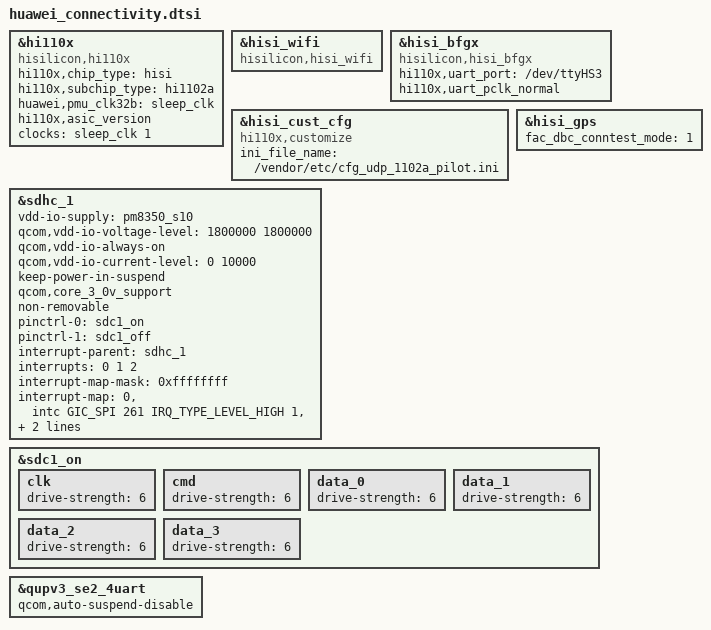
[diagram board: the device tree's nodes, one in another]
&hi110x {
	compatible = "hisilicon,hi110x","hisilicon,hi1102";
	status = "ok";
	hi110x,chip_type = "hisi";
	hi110x,subchip_type = "hi1102a";
	huawei,pmu_clk32b = "sleep_clk";
	hi110x,asic_version;
	clocks = <&sleep_clk 1>;
	clock-names = "sleep_clk";
};

&hisi_wifi {
	compatible = "hisilicon,hisi_wifi";
	status = "ok";
};

&hisi_bfgx {
	compatible = "hisilicon,hisi_bfgx";
	status = "ok";
	hi110x,uart_port = "/dev/ttyHS3";
	hi110x,uart_pclk_normal;
};

&hisi_cust_cfg {
	compatible = "hi110x,customize";
	status = "ok";
	ini_file_name = "/vendor/etc/cfg_udp_1102a_pilot.ini";
};

&hisi_gps {
	/* conndevcheck mode. 1: open, 0: default */
	fac_dbc_conntest_mode = "1";
};

&sdhc_1 {
	vdd-io-supply = <&pm8350_s10>;
	qcom,vdd-io-voltage-level = <1800000 1800000>;
	qcom,vdd-io-always-on;
	qcom,vdd-io-current-level = <0 10000>;

	keep-power-in-suspend;
	qcom,core_3_0v_support;
	non-removable;

	pinctrl-names = "default", "sleep";
	pinctrl-0 = <&sdc1_on>;
	pinctrl-1 = <&sdc1_off>;

	#address-cells = <0>;
	interrupt-parent = <&sdhc_1>;
	interrupts = <0 1 2>;
	#interrupt-cells = <1>;
	interrupt-map-mask = <0xffffffff>;
	interrupt-map = <0 &intc GIC_SPI 261 IRQ_TYPE_LEVEL_HIGH
	1 &intc GIC_SPI 227 IRQ_TYPE_LEVEL_HIGH
	2 &tlmm 228 IRQ_TYPE_LEVEL_HIGH>;
	interrupt-names = "hc_irq", "pwr_irq";

	status = "ok";
};

&sdc1_on {
	clk {
		drive-strength = <6>;
	};

	cmd {
		drive-strength = <6>;
	};

	data_0 {
		drive-strength = <6>;
	};

	data_1 {
		drive-strength = <6>;
	};

	data_2 {
		drive-strength = <6>;
	};

	data_3 {
		drive-strength = <6>;
	};
};

&qupv3_se2_4uart{
	qcom,auto-suspend-disable;
	status = "ok";
};
